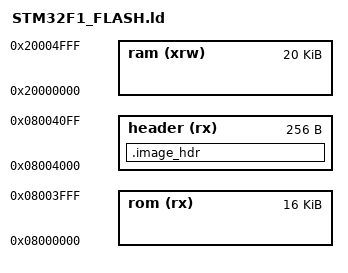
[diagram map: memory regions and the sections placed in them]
/*
******************************************************************************
**

**  File        : LinkerScript.ld
**
**  Author		: Auto-generated by System Workbench for STM32
**
**  Abstract    : Linker script for STM32F103C8Tx series
**                64Kbytes rom and 20Kbytes ram
**
**                Set heap size, stack size and stack location according
**                to application requirements.
**
**                Set memory bank area and size if external memory is used.
**
**  Target      : STMicroelectronics STM32
**
**  Distribution: The file is distributed “as is,” without any warranty
**                of any kind.
**
*****************************************************************************
** @attention
**
** <h2><center>&copy; COPYRIGHT(c) 2019 STMicroelectronics</center></h2>
**
** Redistribution and use in source and binary forms, with or without modification,
** are permitted provided that the following conditions are met:
**   1. Redistributions of source code must retain the above copyright notice,
**      this list of conditions and the following disclaimer.
**   2. Redistributions in binary form must reproduce the above copyright notice,
**      this list of conditions and the following disclaimer in the documentation
**      and/or other materials provided with the distribution.
**   3. Neither the name of STMicroelectronics nor the names of its contributors
**      may be used to endorse or promote products derived from this software
**      without specific prior written permission.
**
** THIS SOFTWARE IS PROVIDED BY THE COPYRIGHT HOLDERS AND CONTRIBUTORS "AS IS"
** AND ANY EXPRESS OR IMPLIED WARRANTIES, INCLUDING, BUT NOT LIMITED TO, THE
** IMPLIED WARRANTIES OF MERCHANTABILITY AND FITNESS FOR A PARTICULAR PURPOSE ARE
** DISCLAIMED. IN NO EVENT SHALL THE COPYRIGHT HOLDER OR CONTRIBUTORS BE LIABLE
** FOR ANY DIRECT, INDIRECT, INCIDENTAL, SPECIAL, EXEMPLARY, OR CONSEQUENTIAL
** DAMAGES (INCLUDING, BUT NOT LIMITED TO, PROCUREMENT OF SUBSTITUTE GOODS OR
** SERVICES; LOSS OF USE, DATA, OR PROFITS; OR BUSINESS INTERRUPTION) HOWEVER
** CAUSED AND ON ANY THEORY OF LIABILITY, WHETHER IN CONTRACT, STRICT LIABILITY,
** OR TORT (INCLUDING NEGLIGENCE OR OTHERWISE) ARISING IN ANY WAY OUT OF THE USE
** OF THIS SOFTWARE, EVEN IF ADVISED OF THE POSSIBILITY OF SUCH DAMAGE.
**
*****************************************************************************
*/

/* Specify the memory areas */
MEMORY
{
  ram (xrw)     : ORIGIN = 0x20000000, LENGTH = 20K
  rom (rx)      : ORIGIN = 0x8000000, LENGTH = 0x0004000
  header (rx)   : ORIGIN = 0x8004000, LENGTH = 0x0000100
}

__app_start = ORIGIN(header) + LENGTH(header);

SECTIONS
{
  .image_hdr : {
    __image_hdr_start = .;
    KEEP (*(.image_hdr))
    __image_hdr_end = .;
  } > header
}

INCLUDE cortex-m-generic.ld
